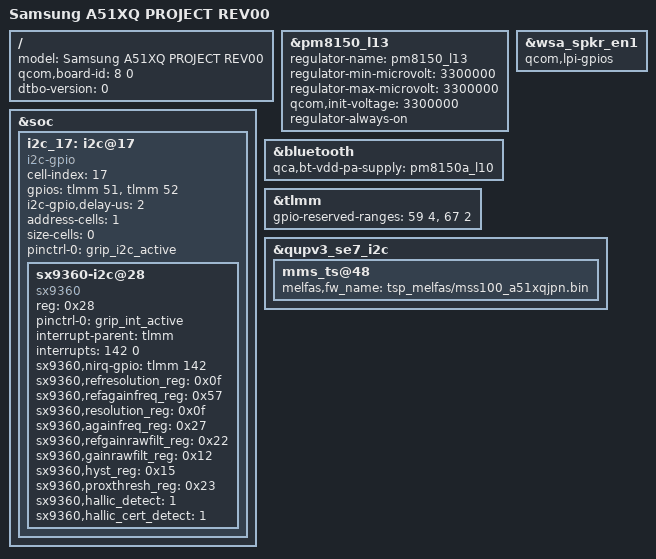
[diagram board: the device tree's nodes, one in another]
#include "lito-sec-a51xq-pinctrl-r00.dtsi"
#include "lito-sec-a51xq-display-r00.dtsi"
#include "../../../../../../../techpack/display/msm/samsung/EA8076A_AMS646UJ10/dsi_panel_EA8076A_AMS646UJ10_fhd_octa_cmd_jpn.dtsi"
#include "../lito-sec-a51-pm-r00.dtsi"

&pm8150_l13 {
	regulator-name = "pm8150_l13";
	regulator-min-microvolt = <3300000>;
	regulator-max-microvolt = <3300000>;
	qcom,init-voltage = <3300000>;
	regulator-always-on;
};

&soc {

	i2c_17: i2c@17 { /* SW I2C */
		status = "ok";

		cell-index = <17>;
		compatible = "i2c-gpio";
		gpios = <&tlmm 51 0 /* sda */
			&tlmm 52 0 /* scl */
			>;
		i2c-gpio,delay-us = <2>;
		address-cells = <1>;
		size-cells = <0>;
		pinctrl-names = "default";
		pinctrl-0 = <&grip_i2c_active>;

		sx9360-i2c@28 {
			compatible = "sx9360";
			reg = <0x28>;
			status = "okay";
			pinctrl-names = "default";
			pinctrl-0 = <&grip_int_active>;
			interrupt-parent = <&tlmm>;
			interrupts = <142 0>;
			sx9360,nirq-gpio = <&tlmm 142 0>;
			sx9360,refresolution_reg = <0x0f>; /* same as resolution_reg */
			sx9360,refagainfreq_reg = <0x57>; /* same as againfreq_reg */
			sx9360,resolution_reg = <0x0f>; /* resolution : 1024 */
			sx9360,againfreq_reg = <0x27>; /* freq : 71.43 kHz, again : +/-3.75 pF */
			sx9360,refgainrawfilt_reg = <0x22>; /* same as gainrawfilt_reg */
			sx9360,gainrawfilt_reg = <0x12>; /* rawfilter : 1-1/4, gain : x2 */
			sx9360,hyst_reg = <0x15>; /* hysteresis : +/-6 %, debouncer : 2 samples */
			sx9360,proxthresh_reg = <0x23>; /* threshhold : 612 */
			sx9360,hallic_detect = <1>;
			sx9360,hallic_cert_detect = <1>;
		};
	};
};

&bluetooth {
	qca,bt-vdd-pa-supply = <&pm8150a_l10>;
};

#if !defined(CONFIG_SEC_FACTORY)
&tlmm {
	gpio-reserved-ranges = 
				<59 4>, /* ENABLE_SENSORS_FPRINT_SECURE */
				<67 2> /* MST_DATA_A, MST_DATA_B */
				;
};
#endif

&wsa_spkr_en1 {
	qcom,lpi-gpios;	
};

&qupv3_se7_i2c {
	mms_ts@48 {
		melfas,fw_name = "tsp_melfas/mss100_a51xqjpn.bin";
	};
};

/ {
	model = "Samsung A51XQ PROJECT REV00";
	qcom,board-id = <8 0>;
	dtbo-version = <0>;
};

